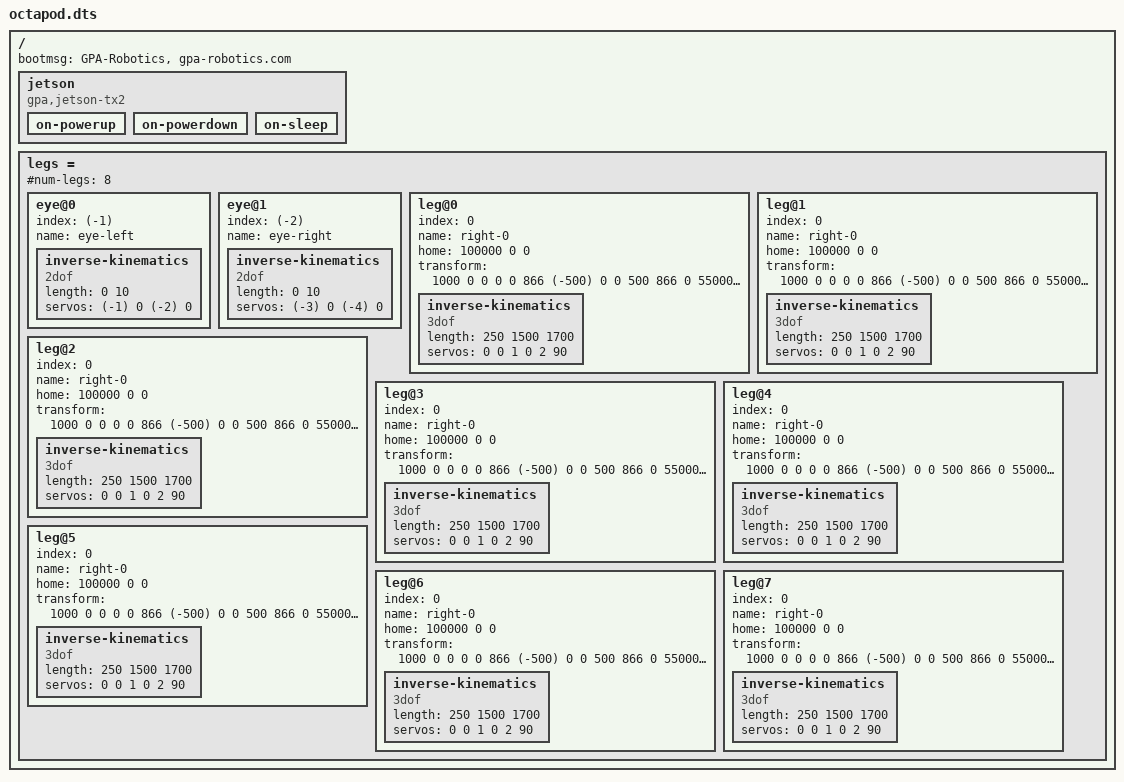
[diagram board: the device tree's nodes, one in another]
/dts-v1/;

/ {
    /*Boot message displayed on LCD*/
    bootmsg = "GPA-Robotics","gpa-robotics.com";

    jetson {
        compatible = "gpa,jetson-tx2";

        on-powerup {
            //gait =  < &all-stand >;
        };

        on-powerdown {
            //gait =  < &all-home >;
        };

        on-sleep {
            //gait =  < &all-home >;
        };


    };

    legs = {
        /*Number of legs*/
        #num-legs = < 8 >;

        eye@0 {
            index = < (-1) >;
            name = "eye-left";
            inverse-kinematics {
                /*IK driver*/
                compatible = "2dof";

                /*Length in mm*10*/
                length = < 0 10 >;

                /*Servo indices and offset*/
                servos = <
                    (-1) 0
                    (-2) 0
                >;
            };
        };

        eye@1 {
            index = < (-2) >;
            name = "eye-right";
            inverse-kinematics {
                /*IK driver*/
                compatible = "2dof";

                /*Length in mm*10*/
                length = < 0 10 >;

                /*Servo indices and offset*/
                servos = <
                    (-3) 0
                    (-4) 0
                >;
            };
        };

        leg@0 {
            /*Index of leg*/
            index = 0;

            /*Name of leg*/
            name = "right-0";

            /*Home coordinates (leg local-space)*/
            home = < 100000 0 0 >;

            /*Matrix used to transform to leg local-space, scaled by 1000*/
            transform = <
                1000    0       0       0
                0       866     (-500)  0
                0       500     866     0
                55000   150000  0       1000
            >;

            inverse-kinematics {
                /*IK driver*/
                compatible = "3dof";

                /*Length in mm*10*/
                length = < 250 1500 1700 >;

                /* index offset */
                servos = <
                    0 0     /*Base joint*/
                    1 0     /*Hip joint*/
                    2 90    /*Foot joint*/
                >;

            };
        };
        leg@1 {
            /*Index of leg*/
            index = 0;

            /*Name of leg*/
            name = "right-0";

            /*Home coordinates (leg local-space)*/
            home = < 100000 0 0 >;

            /*Matrix used to transform to leg local-space, scaled by 1000*/
            transform = <
                1000    0       0       0
                0       866     (-500)  0
                0       500     866     0
                55000   150000  0       1000
            >;

            inverse-kinematics {
                /*IK driver*/
                compatible = "3dof";

                /*Length in mm*10*/
                length = < 250 1500 1700 >;

                /* index offset */
                servos = <
                    0 0     /*Base joint*/
                    1 0     /*Hip joint*/
                    2 90    /*Foot joint*/
                >;

            };
        };
        leg@2 {
            /*Index of leg*/
            index = 0;

            /*Name of leg*/
            name = "right-0";

            /*Home coordinates (leg local-space)*/
            home = < 100000 0 0 >;

            /*Matrix used to transform to leg local-space, scaled by 1000*/
            transform = <
                1000    0       0       0
                0       866     (-500)  0
                0       500     866     0
                55000   150000  0       1000
            >;

            inverse-kinematics {
                /*IK driver*/
                compatible = "3dof";

                /*Length in mm*10*/
                length = < 250 1500 1700 >;

                /* index offset */
                servos = <
                    0 0     /*Base joint*/
                    1 0     /*Hip joint*/
                    2 90    /*Foot joint*/
                >;

            };
        };
        leg@3 {
            /*Index of leg*/
            index = 0;

            /*Name of leg*/
            name = "right-0";

            /*Home coordinates (leg local-space)*/
            home = < 100000 0 0 >;

            /*Matrix used to transform to leg local-space, scaled by 1000*/
            transform = <
                1000    0       0       0
                0       866     (-500)  0
                0       500     866     0
                55000   150000  0       1000
            >;

            inverse-kinematics {
                /*IK driver*/
                compatible = "3dof";

                /*Length in mm*10*/
                length = < 250 1500 1700 >;

                /* index offset */
                servos = <
                    0 0     /*Base joint*/
                    1 0     /*Hip joint*/
                    2 90    /*Foot joint*/
                >;

            };
        };
        leg@4 {
            /*Index of leg*/
            index = 0;

            /*Name of leg*/
            name = "right-0";

            /*Home coordinates (leg local-space)*/
            home = < 100000 0 0 >;

            /*Matrix used to transform to leg local-space, scaled by 1000*/
            transform = <
                1000    0       0       0
                0       866     (-500)  0
                0       500     866     0
                55000   150000  0       1000
            >;

            inverse-kinematics {
                /*IK driver*/
                compatible = "3dof";

                /*Length in mm*10*/
                length = < 250 1500 1700 >;

                /* index offset */
                servos = <
                    0 0     /*Base joint*/
                    1 0     /*Hip joint*/
                    2 90    /*Foot joint*/
                >;

            };
        };
        leg@5 {
            /*Index of leg*/
            index = 0;

            /*Name of leg*/
            name = "right-0";

            /*Home coordinates (leg local-space)*/
            home = < 100000 0 0 >;

            /*Matrix used to transform to leg local-space, scaled by 1000*/
            transform = <
                1000    0       0       0
                0       866     (-500)  0
                0       500     866     0
                55000   150000  0       1000
            >;

            inverse-kinematics {
                /*IK driver*/
                compatible = "3dof";

                /*Length in mm*10*/
                length = < 250 1500 1700 >;

                /* index offset */
                servos = <
                    0 0     /*Base joint*/
                    1 0     /*Hip joint*/
                    2 90    /*Foot joint*/
                >;

            };
        };
        leg@6 {
            /*Index of leg*/
            index = 0;

            /*Name of leg*/
            name = "right-0";

            /*Home coordinates (leg local-space)*/
            home = < 100000 0 0 >;

            /*Matrix used to transform to leg local-space, scaled by 1000*/
            transform = <
                1000    0       0       0
                0       866     (-500)  0
                0       500     866     0
                55000   150000  0       1000
            >;

            inverse-kinematics {
                /*IK driver*/
                compatible = "3dof";

                /*Length in mm*10*/
                length = < 250 1500 1700 >;

                /* index offset */
                servos = <
                    0 0     /*Base joint*/
                    1 0     /*Hip joint*/
                    2 90    /*Foot joint*/
                >;

            };
        };
        leg@7 {
            /*Index of leg*/
            index = 0;

            /*Name of leg*/
            name = "right-0";

            /*Home coordinates (leg local-space)*/
            home = < 100000 0 0 >;

            /*Matrix used to transform to leg local-space, scaled by 1000*/
            transform = <
                1000    0       0       0
                0       866     (-500)  0
                0       500     866     0
                55000   150000  0       1000
            >;

            inverse-kinematics {
                /*IK driver*/
                compatible = "3dof";

                /*Length in mm*10*/
                length = < 250 1500 1700 >;

                /* index offset */
                servos = <
                    0 0     /*Base joint*/
                    1 0     /*Hip joint*/
                    2 90    /*Foot joint*/
                >;

            };
        };

    };
};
